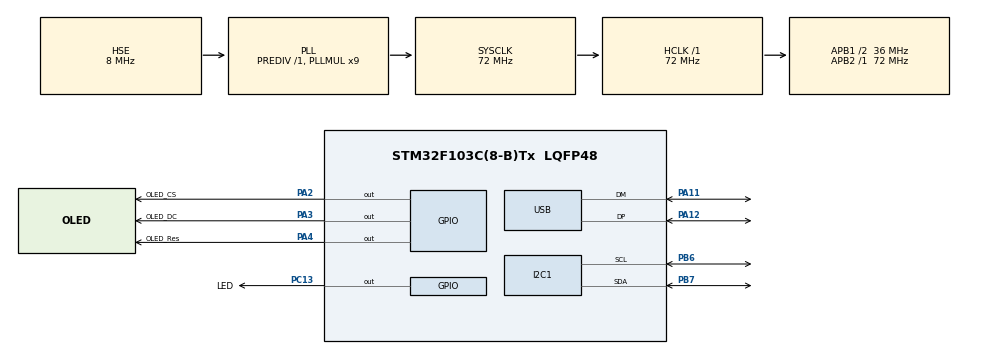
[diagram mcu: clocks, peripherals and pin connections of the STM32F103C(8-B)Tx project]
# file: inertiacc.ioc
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FREERTOS.Tasks01=defaultTask,0,128,StartDefaultTask,Default,NULL,Dynamic,NULL,NULL
I2C1.I2C_Mode=I2C_Fast
Mcu.Family=STM32F1
Mcu.Name=STM32F103C(8-B)Tx
Mcu.Package=LQFP48
NVIC.PriorityGroup=NVIC_PRIORITYGROUP_4
NVIC.TIM4_IRQn=true\:15\:0\:false\:false\:true\:false\:false\:true\:true
NVIC.TimeBase=TIM4_IRQn
NVIC.TimeBaseIP=TIM4
NVIC.USB_LP_CAN1_RX0_IRQn=true\:5\:0\:false\:false\:true\:true\:false\:true\:true
PA11.Mode=Device
PA11.Signal=USB_DM
PA12.Mode=Device
PA12.Signal=USB_DP
PA13.Mode=Serial_Wire
PA13.Signal=SYS_JTMS-SWDIO
PA14.Mode=Serial_Wire
PA14.Signal=SYS_JTCK-SWCLK
PA2.GPIO_Label=OLED_CS
PA2.Signal=GPIO_Output
PA3.GPIO_Label=OLED_DC
PA3.Signal=GPIO_Output
PA4.GPIO_Label=OLED_Res
PA4.Signal=GPIO_Output
PB6.Mode=I2C
PB6.Signal=I2C1_SCL
PB7.Mode=I2C
PB7.Signal=I2C1_SDA
PC13-TAMPER-RTC.GPIO_Label=LED
PC13-TAMPER-RTC.Signal=GPIO_Output
PD0-OSC_IN.Mode=HSE-External-Oscillator
PD0-OSC_IN.Signal=RCC_OSC_IN
PD1-OSC_OUT.Mode=HSE-External-Oscillator
PD1-OSC_OUT.Signal=RCC_OSC_OUT
ProjectManager.HeapSize=0x200
ProjectManager.StackSize=0x400
ProjectManager.TargetToolchain=CMake
RCC.AHBFreq_Value=72000000
RCC.APB1CLKDivider=RCC_HCLK_DIV2
RCC.APB1Freq_Value=36000000
RCC.APB1TimFreq_Value=72000000
RCC.APB2Freq_Value=72000000
RCC.APB2TimFreq_Value=72000000
RCC.HCLKFreq_Value=72000000
RCC.PLLMUL=RCC_PLL_MUL9
RCC.PLLSourceVirtual=RCC_PLLSOURCE_HSE
RCC.SYSCLKFreq_VALUE=72000000
RCC.SYSCLKSource=RCC_SYSCLKSOURCE_PLLCLK
RCC.USBFreq_Value=48000000
RCC.USBPrescaler=RCC_USBCLKSOURCE_PLL_DIV1_5
USB_DEVICE.CLASS_NAME_FS=HID
USB_DEVICE.CONFIGURATION_STRING_HID_FS=MIDI Config
USB_DEVICE.INTERFACE_STRING_HID_FS=MIDI Interface
USB_DEVICE.PRODUCT_STRING_HID_FS=STM32 MIDI interface
USB_DEVICE.USBD_SELF_POWERED=0
USB_DEVICE.VirtualMode=Hid
USB_DEVICE.VirtualModeFS=Hid_FS
VP_FREERTOS_VS_CMSIS_V1.Mode=CMSIS_V1
VP_SYS_VS_tim4.Mode=TIM4
VP_USB_DEVICE_VS_USB_DEVICE_HID_FS.Mode=HID_FS
board=custom

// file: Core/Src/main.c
/* USER CODE BEGIN Header */
/**
  ******************************************************************************
  * @file           : main.c
  * @brief          : Main program body
  ******************************************************************************
  * @attention
  *
  * Copyright (c) 2024 STMicroelectronics.
  * All rights reserved.
  *
  * This software is licensed under terms that can be found in the LICENSE file
  * in the root directory of this software component.
  * If no LICENSE file comes with this software, it is provided AS-IS.
  *
  ******************************************************************************
  */
/* USER CODE END Header */
#include "main.h"
#include "cmsis_os.h"
#include "i2c.h"
#include "usb_device.h"
#include "gpio.h"

void SystemClock_Config(void);
void MX_FREERTOS_Init(void);

int main(void)
{

  /* MCU Configuration--------------------------------------------------------*/

  /* Reset of all peripherals, Initializes the Flash interface and the Systick. */
  HAL_Init();

  /* Configure the system clock */
  SystemClock_Config();

  /* Initialize all configured peripherals */
  MX_GPIO_Init();
  MX_I2C1_Init();

  /* Call init function for freertos objects (in freertos.c) */
  MX_FREERTOS_Init();

  /* Start scheduler */
  osKernelStart();

  /* We should never get here as control is now taken by the scheduler */
  /* Infinite loop */
  while (1)
  {

  }
}

void SystemClock_Config(void)
{
  RCC_OscInitTypeDef RCC_OscInitStruct = {0};
  RCC_ClkInitTypeDef RCC_ClkInitStruct = {0};
  RCC_PeriphCLKInitTypeDef PeriphClkInit = {0};

  /** Initializes the RCC Oscillators according to the specified parameters
  * in the RCC_OscInitTypeDef structure.
  */
  RCC_OscInitStruct.OscillatorType = RCC_OSCILLATORTYPE_HSE;
  RCC_OscInitStruct.HSEState = RCC_HSE_ON;
  RCC_OscInitStruct.HSEPredivValue = RCC_HSE_PREDIV_DIV1;
  RCC_OscInitStruct.HSIState = RCC_HSI_ON;
  RCC_OscInitStruct.PLL.PLLState = RCC_PLL_ON;
  RCC_OscInitStruct.PLL.PLLSource = RCC_PLLSOURCE_HSE;
  RCC_OscInitStruct.PLL.PLLMUL = RCC_PLL_MUL9;
  if (HAL_RCC_OscConfig(&RCC_OscInitStruct) != HAL_OK)
  {
    Error_Handler();
  }

  /** Initializes the CPU, AHB and APB buses clocks
  */
  RCC_ClkInitStruct.ClockType = RCC_CLOCKTYPE_HCLK|RCC_CLOCKTYPE_SYSCLK
                              |RCC_CLOCKTYPE_PCLK1|RCC_CLOCKTYPE_PCLK2;
  RCC_ClkInitStruct.SYSCLKSource = RCC_SYSCLKSOURCE_PLLCLK;
  RCC_ClkInitStruct.AHBCLKDivider = RCC_SYSCLK_DIV1;
  RCC_ClkInitStruct.APB1CLKDivider = RCC_HCLK_DIV2;
  RCC_ClkInitStruct.APB2CLKDivider = RCC_HCLK_DIV1;

  if (HAL_RCC_ClockConfig(&RCC_ClkInitStruct, FLASH_LATENCY_2) != HAL_OK)
  {
    Error_Handler();
  }
  PeriphClkInit.PeriphClockSelection = RCC_PERIPHCLK_USB;
  PeriphClkInit.UsbClockSelection = RCC_USBCLKSOURCE_PLL_DIV1_5;
  if (HAL_RCCEx_PeriphCLKConfig(&PeriphClkInit) != HAL_OK)
  {
    Error_Handler();
  }
}

void HAL_TIM_PeriodElapsedCallback(TIM_HandleTypeDef *htim)
{
  if (htim->Instance == TIM4) {
    HAL_IncTick();
  }
}

void Error_Handler(void)
{
  __disable_irq();
  while (1)
  {
  }
}

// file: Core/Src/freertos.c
/* USER CODE BEGIN Header */
/**
  ******************************************************************************
  * File Name          : freertos.c
  * Description        : Code for freertos applications
  ******************************************************************************
  * @attention
  *
  * Copyright (c) 2024 STMicroelectronics.
  * All rights reserved.
  *
  * This software is licensed under terms that can be found in the LICENSE file
  * in the root directory of this software component.
  * If no LICENSE file comes with this software, it is provided AS-IS.
  *
  ******************************************************************************
  */
/* USER CODE END Header */

#include "FreeRTOS.h"
#include "task.h"
#include "main.h"
#include "cmsis_os.h"

/* USER CODE BEGIN Variables */
osThreadId imuTaskHandle;
osThreadId ledTaskHandle;
osThreadId midiTaskHandle;
/* USER CODE END Variables */
osThreadId defaultTaskHandle;

/* USER CODE BEGIN FunctionPrototypes */
void imuTask(void *pv_arg);
void ledTask(void *pv_arg);
void midiTask(void *pv_arg);
/* USER CODE END FunctionPrototypes */

void StartDefaultTask(void const * argument);

extern void MX_USB_DEVICE_Init(void);
void MX_FREERTOS_Init(void); /* (MISRA C 2004 rule 8.1) */

/* GetIdleTaskMemory prototype (linked to static allocation support) */
void vApplicationGetIdleTaskMemory( StaticTask_t **ppxIdleTaskTCBBuffer, StackType_t **ppxIdleTaskStackBuffer, uint32_t *pulIdleTaskStackSize );

/* USER CODE BEGIN GET_IDLE_TASK_MEMORY */
static StaticTask_t xIdleTaskTCBBuffer;
static StackType_t xIdleStack[configMINIMAL_STACK_SIZE];

void vApplicationGetIdleTaskMemory( StaticTask_t **ppxIdleTaskTCBBuffer, StackType_t **ppxIdleTaskStackBuffer, uint32_t *pulIdleTaskStackSize )
{
  *ppxIdleTaskTCBBuffer = &xIdleTaskTCBBuffer;
  *ppxIdleTaskStackBuffer = &xIdleStack[0];
  *pulIdleTaskStackSize = configMINIMAL_STACK_SIZE;
  /* place for user code */
}
/* USER CODE END GET_IDLE_TASK_MEMORY */

void MX_FREERTOS_Init(void) {

  /* Create the thread(s) */
  /* definition and creation of defaultTask */
  osThreadDef(defaultTask, StartDefaultTask, osPriorityNormal, 0, 128);
  defaultTaskHandle = osThreadCreate(osThread(defaultTask), NULL);

  /* USER CODE BEGIN RTOS_THREADS */
  /* add threads, ... */
  osThreadDef(ledTask, ledTask, osPriorityNormal, 0, 64);
  ledTaskHandle = osThreadCreate(osThread(ledTask), NULL);

  osThreadDef(imuTask, imuTask, osPriorityNormal, 0, 128);
  imuTaskHandle = osThreadCreate(osThread(imuTask), NULL);

  osThreadDef(midiTask, midiTask, osPriorityNormal, 0, 128);
  midiTaskHandle = osThreadCreate(osThread(midiTask), NULL);
  /* USER CODE END RTOS_THREADS */

}

void StartDefaultTask(void const * argument)
{
  /* init code for USB_DEVICE */
  MX_USB_DEVICE_Init();
  for(;;)
  {
    osDelay(1);
  }
}
